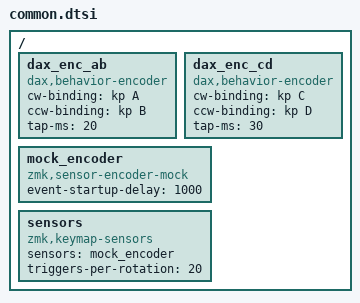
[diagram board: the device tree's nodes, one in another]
#include <behaviors.dtsi>
#include <dt-bindings/zmk/keys.h>
#include <dt-bindings/zmk/kscan_mock.h>

// An encoder mock as ZMK's own tests/encoders use: 20 steps a turn, so 18 degrees is one step.
/ {
    dax_enc_ab: dax_enc_ab {
        compatible = "dax,behavior-encoder";
        #sensor-binding-cells = <0>;
        cw-binding = <&kp A>;
        ccw-binding = <&kp B>;
        tap-ms = <20>;
    };

    dax_enc_cd: dax_enc_cd {
        compatible = "dax,behavior-encoder";
        #sensor-binding-cells = <0>;
        cw-binding = <&kp C>;
        ccw-binding = <&kp D>;
        tap-ms = <30>;
    };

    mock_encoder: mock_encoder {
        compatible = "zmk,sensor-encoder-mock";
        status = "okay";
        event-startup-delay = <1000>;
    };

    sensors: sensors {
        compatible = "zmk,keymap-sensors";
        sensors = <&mock_encoder>;
        triggers-per-rotation = <20>;
    };
};
